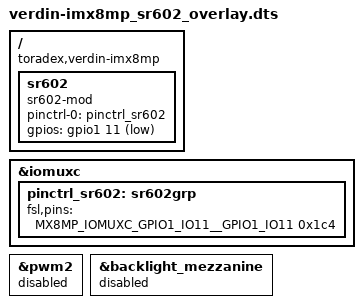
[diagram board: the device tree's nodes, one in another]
/dts-v1/;
/plugin/;

#include "imx8mp-pinfunc.h"
#include <dt-bindings/gpio/gpio.h>
#include <dt-bindings/input/linux-event-codes.h>
#include <dt-bindings/interrupt-controller/irq.h>

/ {
    compatible = "toradex,verdin-imx8mp";

    fragment@0 {
        target = <&iomuxc>;
        __overlay__ {
            pinctrl_sr602: sr602grp {
                fsl,pins = <
                    MX8MP_IOMUXC_GPIO1_IO11__GPIO1_IO11          0x1c4
                >;
            };
        };
    };

    fragment@1 {
        target-path = "/";
        __overlay__ {
            sr602 {
                compatible = "sr602-mod";
                pinctrl-names = "default";
                pinctrl-0 = <&pinctrl_sr602>;
                gpios = <&gpio1 11 GPIO_ACTIVE_LOW>;
            };
        };
    };

    /* Disable PWM_2 which is on the same pin (SODIMM 16) */
    fragment@2 {
        target = <&pwm2>;
        __overlay__ {
            status = "disabled";
        };
    };

    /* Disable backlight mezzanine which might use PWM_2 */
    fragment@3 {
        target = <&backlight_mezzanine>;
        __overlay__ {
            status = "disabled";
        };
    };
};
